# cmem7 register map
File version: 1.0
Registers are 32-bit, read-write, reset 0x0 unless marked. A register's access mark holds for its fields unless they carry their own. Offsets are from the block's base; [hi:lo] are bit positions; {n}, {i} and the like mark numbered series; 'fields as' and 'values as' point back to an identical list.

## WDG — watchdog
Base 0x41001000
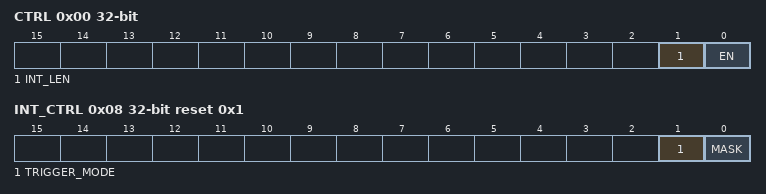
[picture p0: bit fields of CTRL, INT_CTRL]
0x00 CTRL — control Register
  [1] INT_LEN — watchdog report interrupt when COUNTER is 1/4 or 1/2 of LENGTH
    0=INT_LEN_QUARTER (watchdog report interrupt when COUNTER is 1/4 of LENGTH); 1=INT_LEN_HALF (watchdog report interrupt when COUNTER is 1/2 of LENGTH)
  [0] EN — flag indicates if watchdog is enabled or not
0x04 LEN — Ticks decrease down to 25% or 50% to trigger an interrupt
0x08 INT_CTRL reset 0x1 — interrupt control
  [1] TRIGGER_MODE
    0=TRIGGER_MODE_EDGE (edge trigger); 1=TRIGGER_MODE_LEVEL (level trigger)
  [0] MASK
0x0C INT_STA — interrupt status register
  [0] STA — interrupt status
0x10 INT_RAW — interrupt raw register
  [0] STA — interrupt status
0x14 CNT ro — counter register

## TIMER0
Base 0x41000000
Same registers: TIMER1 0x41000020, TIMER2 0x41000040, TIMER3 0x41000060
0x00 CTRL — control Register
  [0] EN — flag indicates if timer is enabled or not
0x04 TYPE
  [0] SIGNLE_SHOT — indicate timer generate only one interrupt if not reload
0x08 LEN — length
0x0C INT_EN reset 0x1 — interrupt enable
  [0] EN_REVERSE — flag indicates if timer is disable or not
0x10 INT_STA — interrupt status
  [0] STA
0x14 INT_RAW — interrupt raw register
  [0] STA — interrupt status
0x18 CNT ro — counter register

## SPI0
Base 0x41004000
Same registers: SPI1 0x4100B000
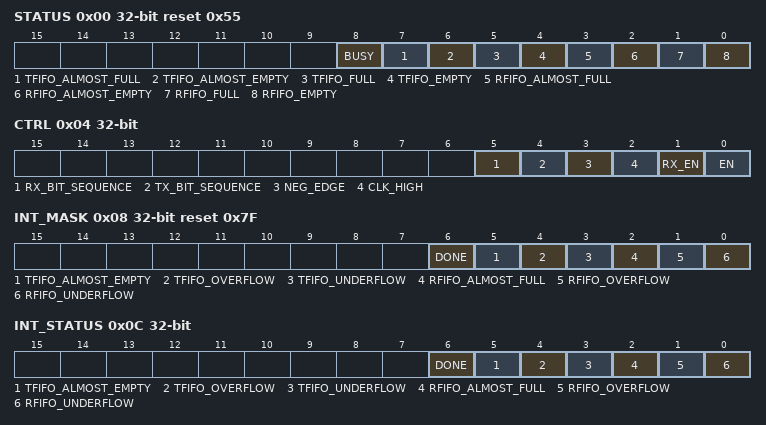
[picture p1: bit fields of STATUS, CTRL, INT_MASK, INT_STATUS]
0x00 STATUS ro reset 0x55
  [8] BUSY — indecates if SPI is idle or busy
  [7] TFIFO_ALMOST_FULL — transmit fifo almost full
  [6] TFIFO_ALMOST_EMPTY — transmit fifo is almost empty
  [5] TFIFO_FULL — transmit fifo is full
  [4] TFIFO_EMPTY — transmit fifo is empty
  [3] RFIFO_ALMOST_FULL — receive fifo almost full
  [2] RFIFO_ALMOST_EMPTY — receive fifo is almost empty
  [1] RFIFO_FULL — receive fifo is full
  [0] RFIFO_EMPTY — receive fifo is empty
0x04 CTRL (reset mask 0xF) — control Register
  [5] RX_BIT_SEQUENCE — receive bit sequence. 0: MSB is received first
  [4] TX_BIT_SEQUENCE — transmit bit sequence. 0 : MSB is sent first
  [3] NEG_EDGE — 1, indicates SPI takes sample at the rise edge and transmit data at the trailing edge. 0, conversely.
  [2] CLK_HIGH — indicats if idle clock polarity is high level
  [1] RX_EN — indicates if SPI receiver is enabled or not
  [0] EN — indicates if SPI is enabled or not
0x08 INT_MASK reset 0x7F — interrupt mask Register
  [6] DONE — transmit done interrupt
  [5] TFIFO_ALMOST_EMPTY — transmit fifo almost empty interrupt
  [4] TFIFO_OVERFLOW — transmit fifo overflow interrupt
  [3] TFIFO_UNDERFLOW — transmit fifo underflow interrupt
  [2] RFIFO_ALMOST_FULL — receive fifo almost full interrupt
  [1] RFIFO_OVERFLOW — receive fifo overflow interrupt
  [0] RFIFO_UNDERFLOW — receive fifo underflow interrupt
0x0C INT_STATUS — interrupt Register
  fields as INT_MASK
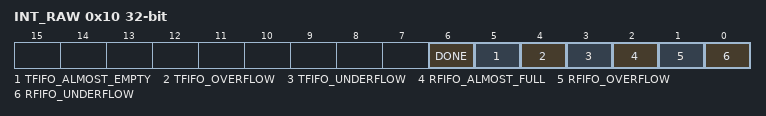
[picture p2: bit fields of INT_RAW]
0x10 INT_RAW — interrupt raw Register
  fields as INT_MASK
0x14 BCNT reset 0x1F — bit length while transmitting and receiving
  [4:0] CNT — bit length while transmitting and receiving, BCNT + 1
0x18 GAP 8-bit reset 0x1 — half cycle number between continuous data frame
0x1C DIV 16-bit — frequency division register, fsck = fclk_io / (DIV + 1) / 2
0x20 TRANS_CNT (reset mask 0xFF) — transmit data length, data number = TRANS_CNT + 1
0x24 TRANS_START wo — transmit startup register, write 1 to trigger transmision once
  [0] TX_TRIGGER — write 1 to trigger transmision once
0x28 RW_DATA — raw data register

## RTC
Base 0x41007004
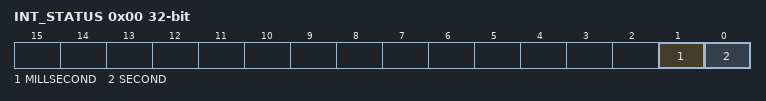
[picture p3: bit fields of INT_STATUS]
0x00 INT_STATUS — interrupt Register
  [1] MILLSECOND — 1ms interrupt, write 1 clear 0
  [0] SECOND — 1s interrupt, write 1 clear 0
0x04 SECOND — current seconds of system time
0x08 MILLSECOND 16-bit — current millseconds of system time
  [9:0] MS — micro seconds

## GPIO
Base 0x41002000
0x00 GPIO_IN ro — GPIO input data
0x04 GPIO_OUT_UNMASK — GPIO output mask Register
0x08 GPIO_OUT_DATA — GPIO output data register
0x0C GPIO_OE — GPIO output driver enable
0x10 GPIO_INT_MASK — GPIO input interrupt mask
0x14 GPIO_INT_STATUS — GPIO input interrupt status
0x18 GPIO_INT_RAW — GPIO input interrupt raw
0x1C GPIO_POSITIVE_EDGE_INT_TRIGGER — triggers an interrupt while a positive edge, else negitive edge
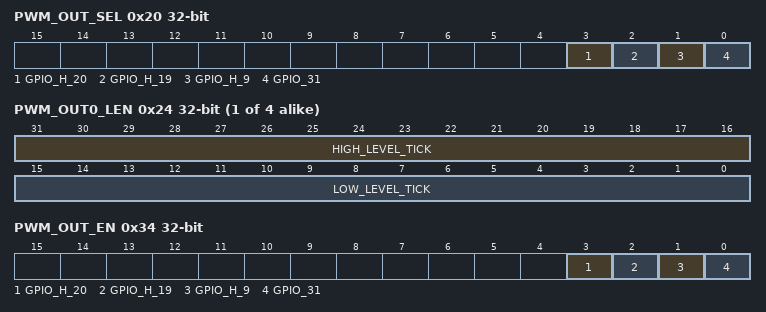
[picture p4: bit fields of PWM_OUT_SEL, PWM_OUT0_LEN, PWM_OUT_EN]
0x20 PWM_OUT_SEL — Select gpio output from PWM
  [3] GPIO_H_20 — GPIO_H[20] is selected to output PWM
  [2] GPIO_H_19 — GPIO_H[19] is selected to output PWM
  [1] GPIO_H_9 — GPIO_H[9] is selected to output PWM
  [0] GPIO_31 — GPIO[31] is selected to output PWM
{0x24+4i} PWM_OUT{i}_LEN (i=0..3) — Pwm channel {i} paramters
  [31:16] HIGH_LEVEL_TICK — high level width = ticks + 1
  [15:0] LOW_LEVEL_TICK — low level width = ticks + 1
0x34 PWM_OUT_EN — Pwm enable
  fields as PWM_OUT_SEL
0x38 GPIO_H_IN ro — GPIO_H input data
0x3C GPIO_H_OUT_UNMASK — GPIO_H output unmask Register
0x40 GPIO_H_OUT_DATA — GPIO_H output data register
0x44 GPIO_H_OE — GPIO_H output driver enable
0x48 GPIO_H_INT_MASK — GPIO_H interrupt mask
0x4C GPIO_H_INT_STATUS — GPIO_H interrupt status
0x50 GPIO_H_INT_RAW — GPIO_H interrupt raw
0x54 GPIO_H_POSITIVE_EDGE_INT_TRIGGER — triggers an interrupt while a positive edge, else negitive edge
0x58 GPIO_N_IN ro — GPIO_N input data
0x5C GPIO_N_OUT_UNMASK — GPIO_N output unmask Register
0x60 GPIO_N_OUT_DATA — GPIO_N output data register
0x64 GPIO_N_OE — GPIO_N output driver enable
0x68 GPIO_N_INT_MASK — GPIO_N interrupt mask
0x6C GPIO_N_INT_STATUS — GPIO_N interrupt status
0x70 GPIO_N_INT_RAW — GPIO_N interrupt raw
0x74 GPIO_N_POSITIVE_EDGE_INT_TRIGGER — triggers an interrupt while a positive edge, else negitive edge
